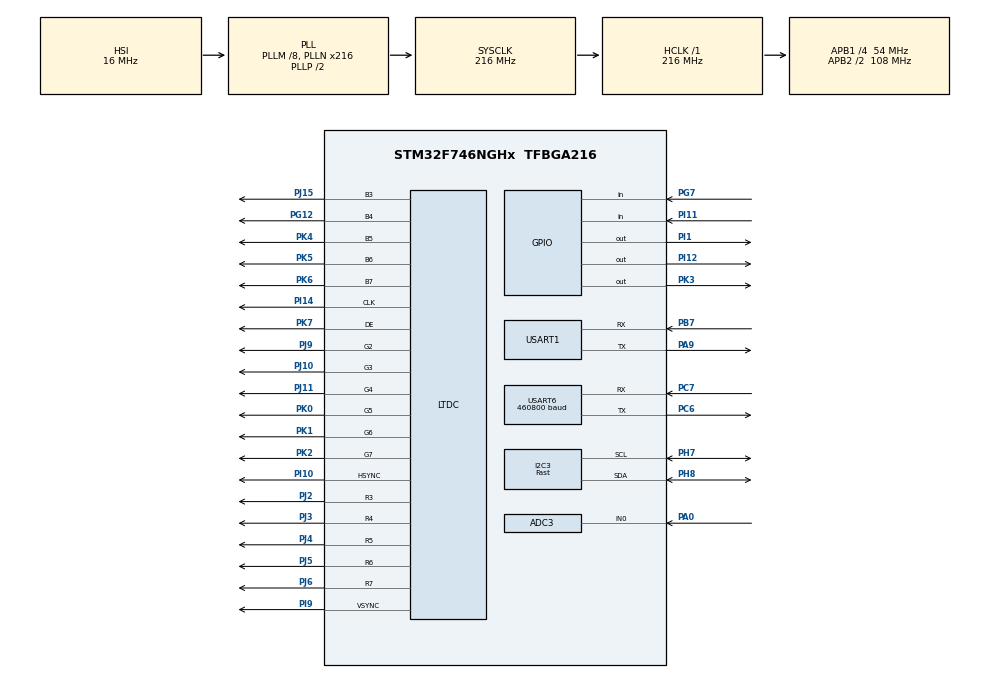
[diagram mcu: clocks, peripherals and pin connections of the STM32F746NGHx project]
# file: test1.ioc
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ADC3.Channel-0\#ChannelRegularConversion=ADC_CHANNEL_0
ADC3.ContinuousConvMode=ENABLE
ADC3.NbrOfConversionFlag=1
ADC3.Rank-0\#ChannelRegularConversion=1
ADC3.SamplingTime-0\#ChannelRegularConversion=ADC_SAMPLETIME_3CYCLES
CORTEX_M7.default_mode_Activation=1
I2C3.I2C_Speed_Mode=I2C_Fast
I2C3.Timing=0x6000030D
LTDC.ActiveH=272
LTDC.ActiveW=480
LTDC.Alpha_L0=255
LTDC.FBStartAdress_L0=0x20010400
LTDC.HBP=43
LTDC.HFP=8
LTDC.HSync=1
LTDC.ImageHeight_L0=272
LTDC.ImageWidth_L0=480
LTDC.Layers=0
LTDC.PixelFormat_L0=LTDC_PIXEL_FORMAT_RGB565
LTDC.VBP=12
LTDC.VFP=4
LTDC.VSync=10
LTDC.WindowX1_L0=480
LTDC.WindowY1_L0=272
Mcu.Family=STM32F7
Mcu.Name=STM32F746NGHx
Mcu.Package=TFBGA216
NVIC.PriorityGroup=NVIC_PRIORITYGROUP_4
NVIC.TIM1_BRK_TIM9_IRQn=true\:0\:0\:false\:false\:true\:true\:true\:true
NVIC.TIM1_UP_TIM10_IRQn=true\:0\:0\:false\:false\:true\:true\:true\:true
NVIC.TIM3_IRQn=true\:0\:0\:false\:false\:true\:true\:true\:true
NVIC.USART1_IRQn=true\:0\:0\:false\:false\:true\:true\:true\:true
NVIC.USART6_IRQn=true\:0\:0\:false\:false\:true\:true\:true\:true
PA0/WKUP.Signal=ADCx_IN0
PA13.Mode=Trace_Asynchronous_SW
PA13.Signal=SYS_JTMS-SWDIO
PA14.Mode=Trace_Asynchronous_SW
PA14.Signal=SYS_JTCK-SWCLK
PA9.Mode=Asynchronous
PA9.Signal=USART1_TX
PB3.Mode=Trace_Asynchronous_SW
PB3.Signal=SYS_JTDO-SWO
PB7.Mode=Asynchronous
PB7.Signal=USART1_RX
PC6.Mode=Asynchronous
PC6.Signal=USART6_TX
PC7.Mode=Asynchronous
PC7.Signal=USART6_RX
PG12.Mode=RGB565
PG12.Signal=LTDC_B4
PG7.GPIO_PuPd=GPIO_PULLDOWN
PG7.Signal=GPIO_Input
PH0/OSC_IN.Mode=HSE-External-Oscillator
PH0/OSC_IN.Signal=RCC_OSC_IN
PH1/OSC_OUT.Mode=HSE-External-Oscillator
PH1/OSC_OUT.Signal=RCC_OSC_OUT
PH7.Mode=I2C
PH7.Signal=I2C3_SCL
PH8.Mode=I2C
PH8.Signal=I2C3_SDA
PI1.PinState=GPIO_PIN_SET
PI1.Signal=GPIO_Output
PI10.Mode=RGB565
PI10.Signal=LTDC_HSYNC
PI11.GPIO_PuPd=GPIO_PULLDOWN
PI11.Signal=GPIO_Input
PI12.PinState=GPIO_PIN_SET
PI12.Signal=GPIO_Output
PI14.Mode=RGB565
PI14.Signal=LTDC_CLK
PI9.Mode=RGB565
PI9.Signal=LTDC_VSYNC
PJ10.Mode=RGB565
PJ10.Signal=LTDC_G3
PJ11.Mode=RGB565
PJ11.Signal=LTDC_G4
PJ15.Mode=RGB565
PJ15.Signal=LTDC_B3
PJ2.Mode=RGB565
PJ2.Signal=LTDC_R3
PJ3.Mode=RGB565
PJ3.Signal=LTDC_R4
PJ4.Mode=RGB565
PJ4.Signal=LTDC_R5
PJ5.Mode=RGB565
PJ5.Signal=LTDC_R6
PJ6.Mode=RGB565
PJ6.Signal=LTDC_R7
PJ9.Mode=RGB565
PJ9.Signal=LTDC_G2
PK0.Mode=RGB565
PK0.Signal=LTDC_G5
PK1.Mode=RGB565
PK1.Signal=LTDC_G6
PK2.Mode=RGB565
PK2.Signal=LTDC_G7
PK3.PinState=GPIO_PIN_SET
PK3.Signal=GPIO_Output
PK4.Mode=RGB565
PK4.Signal=LTDC_B5
PK5.Mode=RGB565
PK5.Signal=LTDC_B6
PK6.Mode=RGB565
PK6.Signal=LTDC_B7
PK7.Mode=RGB565
PK7.Signal=LTDC_DE
ProjectManager.HeapSize=0x200
ProjectManager.StackSize=0x400
ProjectManager.TargetToolchain=MDK-ARM V5.32
RCC.AHBFreq_Value=216000000
RCC.APB1CLKDivider=RCC_HCLK_DIV4
RCC.APB1Freq_Value=54000000
RCC.APB1TimFreq_Value=108000000
RCC.APB2CLKDivider=RCC_HCLK_DIV2
RCC.APB2Freq_Value=108000000
RCC.APB2TimFreq_Value=216000000
RCC.CortexFreq_Value=216000000
RCC.HCLKFreq_Value=216000000
RCC.HSE_VALUE=25000000
RCC.HSI_VALUE=16000000
RCC.LSE_VALUE=32768
RCC.PLLM=8
RCC.PLLN=216
RCC.PLLSAIN=50
RCC.PLLSAIR=5
RCC.SYSCLKFreq_VALUE=216000000
RCC.SYSCLKSource=RCC_SYSCLKSOURCE_PLLCLK
RCC.USBFreq_Value=216000000
RCC.VCOOutputFreq_Value=432000000
SH.ADCx_IN0.0=ADC3_IN0,IN0
TIM1.AutoReloadPreload=TIM_AUTORELOAD_PRELOAD_ENABLE
TIM1.Period=9
TIM1.Prescaler=10800-1
TIM3.AutoReloadPreload=TIM_AUTORELOAD_PRELOAD_ENABLE
TIM3.Period=10000-1
TIM3.Prescaler=10800-1
USART1.VirtualMode-Asynchronous=VM_ASYNC
USART6.BaudRate=460800
USART6.VirtualMode-Asynchronous=VM_ASYNC
VP_TIM1_VS_ClockSourceINT.Mode=Internal
VP_TIM3_VS_ClockSourceINT.Mode=Internal
board=custom

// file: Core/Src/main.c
/* USER CODE BEGIN Header */
/**
  ******************************************************************************
  * @file           : main.c
  * @brief          : Main program body
  ******************************************************************************
  * @attention
  *
  * Copyright (c) 2026 STMicroelectronics.
  * All rights reserved.
  *
  * This software is licensed under terms that can be found in the LICENSE file
  * in the root directory of this software component.
  * If no LICENSE file comes with this software, it is provided AS-IS.
  *
  ******************************************************************************
  */
/* USER CODE END Header */
#include "main.h"
#include "adc.h"
#include "i2c.h"
#include "ltdc.h"
#include "tim.h"
#include "usart.h"
#include "gpio.h"

/* USER CODE BEGIN Includes */
#include "app_main.h"
#include "drv_mpu.h"
/* USER CODE END Includes */

void SystemClock_Config(void);
static void MPU_Config(void);

int main(void)
{

  /* USER CODE BEGIN 1 */
  /* MPU 的完整配置（含 SDRAM / FMC 区域）放到 app_init() 里做。
   * 原因：CubeMX 生成的 MPU_Config() 只配了 region0（其余全部 NO_ACCESS），
   * 它在下面执行，会把 SDRAM 和 FMC 的访问权限关掉；
   * 必须在它之后重新配一次完整的三个区域。 */
  /* USER CODE END 1 */

  /* MPU Configuration--------------------------------------------------------*/
  MPU_Config();

  /* MCU Configuration--------------------------------------------------------*/

  /* Reset of all peripherals, Initializes the Flash interface and the Systick. */
  HAL_Init();

  /* Configure the system clock */
  SystemClock_Config();

  /* Initialize all configured peripherals */
  MX_GPIO_Init();
  MX_TIM3_Init();
  MX_TIM1_Init();
  MX_ADC3_Init();
  MX_USART1_UART_Init();
  MX_I2C3_Init();
  MX_LTDC_Init();
  MX_USART6_UART_Init();
  /* USER CODE BEGIN 2 */
  app_init();
  /* USER CODE END 2 */

  /* Infinite loop */
  while (1)
  {

    /* USER CODE BEGIN 3 */
    app_task();
  }
  /* USER CODE END 3 */
}

void SystemClock_Config(void)
{
  RCC_OscInitTypeDef RCC_OscInitStruct = {0};
  RCC_ClkInitTypeDef RCC_ClkInitStruct = {0};

  /** Configure the main internal regulator output voltage
  */
  __HAL_RCC_PWR_CLK_ENABLE();
  __HAL_PWR_VOLTAGESCALING_CONFIG(PWR_REGULATOR_VOLTAGE_SCALE1);

  /** Initializes the RCC Oscillators according to the specified parameters
  * in the RCC_OscInitTypeDef structure.
  */
  RCC_OscInitStruct.OscillatorType = RCC_OSCILLATORTYPE_HSI;
  RCC_OscInitStruct.HSIState = RCC_HSI_ON;
  RCC_OscInitStruct.HSICalibrationValue = RCC_HSICALIBRATION_DEFAULT;
  RCC_OscInitStruct.PLL.PLLState = RCC_PLL_ON;
  RCC_OscInitStruct.PLL.PLLSource = RCC_PLLSOURCE_HSI;
  RCC_OscInitStruct.PLL.PLLM = 8;
  RCC_OscInitStruct.PLL.PLLN = 216;
  RCC_OscInitStruct.PLL.PLLP = RCC_PLLP_DIV2;
  RCC_OscInitStruct.PLL.PLLQ = 2;
  if (HAL_RCC_OscConfig(&RCC_OscInitStruct) != HAL_OK)
  {
    Error_Handler();
  }

  /** Activate the Over-Drive mode
  */
  if (HAL_PWREx_EnableOverDrive() != HAL_OK)
  {
    Error_Handler();
  }

  /** Initializes the CPU, AHB and APB buses clocks
  */
  RCC_ClkInitStruct.ClockType = RCC_CLOCKTYPE_HCLK|RCC_CLOCKTYPE_SYSCLK
                              |RCC_CLOCKTYPE_PCLK1|RCC_CLOCKTYPE_PCLK2;
  RCC_ClkInitStruct.SYSCLKSource = RCC_SYSCLKSOURCE_PLLCLK;
  RCC_ClkInitStruct.AHBCLKDivider = RCC_SYSCLK_DIV1;
  RCC_ClkInitStruct.APB1CLKDivider = RCC_HCLK_DIV4;
  RCC_ClkInitStruct.APB2CLKDivider = RCC_HCLK_DIV2;

  if (HAL_RCC_ClockConfig(&RCC_ClkInitStruct, FLASH_LATENCY_7) != HAL_OK)
  {
    Error_Handler();
  }
}

 /* MPU Configuration */

void MPU_Config(void)
{
  MPU_Region_InitTypeDef MPU_InitStruct = {0};

  /* Disables the MPU */
  HAL_MPU_Disable();

  /** Initializes and configures the Region and the memory to be protected
  */
  MPU_InitStruct.Enable = MPU_REGION_ENABLE;
  MPU_InitStruct.Number = MPU_REGION_NUMBER0;
  MPU_InitStruct.BaseAddress = 0x0;
  MPU_InitStruct.Size = MPU_REGION_SIZE_4GB;
  MPU_InitStruct.SubRegionDisable = 0x87;
  MPU_InitStruct.TypeExtField = MPU_TEX_LEVEL0;
  MPU_InitStruct.AccessPermission = MPU_REGION_NO_ACCESS;
  MPU_InitStruct.DisableExec = MPU_INSTRUCTION_ACCESS_DISABLE;
  MPU_InitStruct.IsShareable = MPU_ACCESS_SHAREABLE;
  MPU_InitStruct.IsCacheable = MPU_ACCESS_NOT_CACHEABLE;
  MPU_InitStruct.IsBufferable = MPU_ACCESS_NOT_BUFFERABLE;

  HAL_MPU_ConfigRegion(&MPU_InitStruct);
  /* Enables the MPU */
  HAL_MPU_Enable(MPU_PRIVILEGED_DEFAULT);

}

void Error_Handler(void)
{
  __disable_irq();
  while (1)
  {
  }
}
